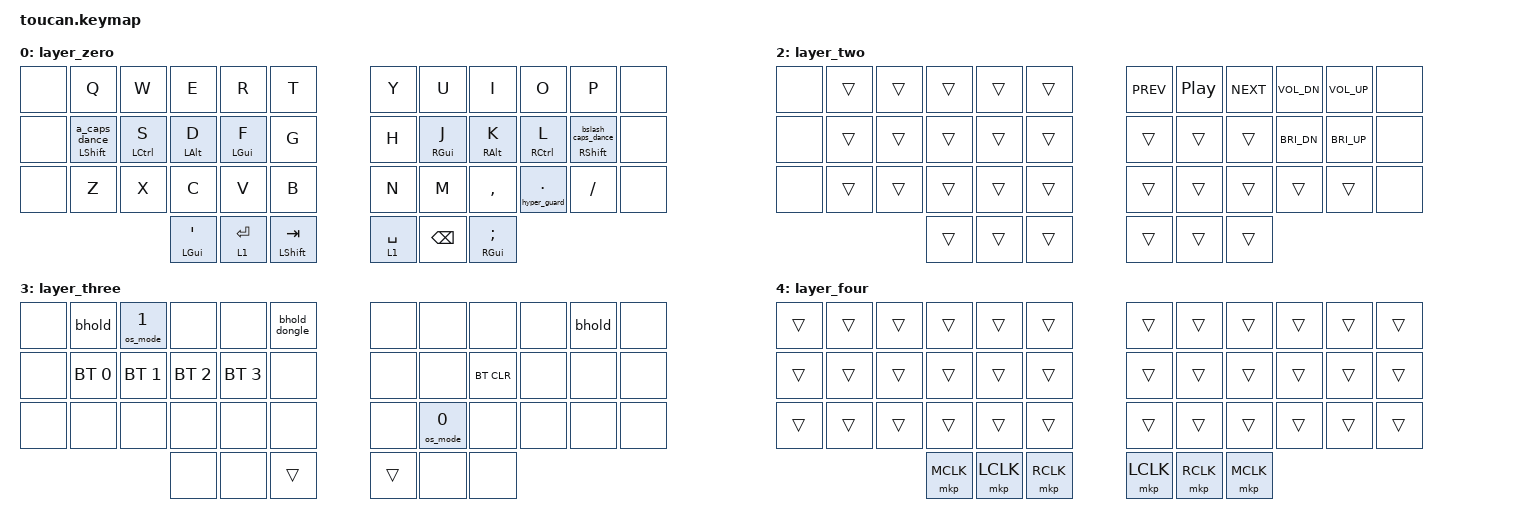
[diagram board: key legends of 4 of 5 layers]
#include <behaviors.dtsi>
#include <dt-bindings/zmk/keys.h>
#include <dt-bindings/zmk/bt.h>
#include <dt-bindings/zmk/outputs.h>
#include <dt-bindings/zmk/pointing.h>

// Home row mods macro
#define HRML(k1,k2,k3,k4) &hml LSHFT k1 &hml LCTRL k2  &hml LALT k3  &hml LGUI k4
#define HRMR(k1,k2,k3,k4) &hmr RGUI k1  &hmr RALT k2  &hmr RCTRL k3  &hmr RSHFT k4

// Key positions for positional hold-tap, kept for reference. Currently unused:
// the homerow mods below deliberately do NOT use cross-hand gating (see the
// note on `hml`). This is a ZMK Toucan2 (42 keys), so numbering below
// matches the shield's matrix transform -- see boards/shields/toucan/toucan.dtsi:
//   Row 0:  0   1  2  3  4  5  |  6  7  8  9 10  11
//   Row 1: 12  13 14 15 16 17  | 18 19 20 21 22  23
//   Row 2: 24  25 26 27 28 29  | 30 31 32 33 34  35
//   Thumbs:       36 37 38     | 39 40 41
// Positions 0, 11, 12, 23, 24, 35 are the outer pinky columns that exist on
// the Toucan's 42-key matrix but have no equivalent on the 36-key totemist
// this keymap was ported from -- they are bound to &none below.
#define KEYS_L 1 2 3 4 5 13 14 15 16 17 25 26 27 28 29    // left-hand inner keys
#define KEYS_R 6 7 8 9 10 18 19 20 21 22 30 31 32 33 34   // right-hand inner keys
#define THUMBS 36 37 38 39 40 41                          // thumb keys
#define UNUSED 0 11 12 23 24 35                           // extra pinky-column keys (no totemist equivalent)

// Layer names are for the USB dongle's OLED, so only the dongle build gets
// them (toucan_dongle.overlay defines TOUCAN_LAYER_NAMES). The left half's
// standalone gem screen keeps its stock `L#n` layer labels.
#ifdef TOUCAN_LAYER_NAMES
#define LAYER_NAME(label) display-name = label;
#else
#define LAYER_NAME(label)
#endif

#define L0 0
#define L1 1
#define L2 2
#define L3 3
#define L4 4

// Layer-tap, used by the left Enter/L1 and right Space/L1 thumbs.
//
// ZMK's stock `&lt` is `tap-preferred`, which only resolves a hold when the
// tapping term expires -- pressing and releasing another key while it is held
// does NOT trigger the hold. So a quick layer chord (hold the thumb, tap a
// key, release) completed inside 200ms emits SPACE plus that key instead of
// the layer keycode. `balanced` resolves the hold as soon as another key is
// pressed and released, which is exactly what a layer chord looks like.
&lt {
    flavor = "balanced";
    tapping-term-ms = <175>;
    quick-tap-ms = <125>;
};

/ {
    behaviors {
        // Thumb hold-tap: quote/Cmd on the left outer thumb and
        // semicolon/Cmd on the right outer thumb.
        //
        // Deliberately has NO `global-quick-tap` / `require-prior-idle-ms`.
        // Those make ZMK resolve the key to an *instant tap* whenever any other
        // key was pressed within the preceding window, no matter how long or
        // how hard the key is then held -- see is_quick_tap() in ZMK's
        // behavior_hold_tap.c. Since Shift is nearly always pressed immediately
        // after typing a letter, that reliably emitted TAB instead of SHIFT.
        //
        // Prior-idle gating is right for homerow mods (see hml/hmr below), but
        // wrong for thumbs, which are never pressed accidentally while typing.
        ht: hold_tap {
            label = "hold_tap";
            compatible = "zmk,behavior-hold-tap";
            #binding-cells = <2>;
            flavor = "balanced";
            tapping-term-ms = <175>;
            quick-tap-ms = <125>;
            bindings = <&kp>, <&kp>;
        };

        a_caps_dance: a_caps_dance {
            compatible = "zmk,behavior-tap-dance";
            #binding-cells = <0>;
            tapping-term-ms = <200>;
            bindings = <&kp A>, <&caps_word>;
        };

        bslash_caps_dance: bslash_caps_dance {
            compatible = "zmk,behavior-tap-dance";
            #binding-cells = <0>;
            tapping-term-ms = <200>;
            bindings = <&kp BSLH>, <&caps_word>;
        };

        a_shift: a_shift {
            compatible = "zmk,behavior-hold-tap";
            #binding-cells = <2>;
            flavor = "balanced";
            tapping-term-ms = <190>;
            quick-tap-ms = <120>;
            require-prior-idle-ms = <100>;
            bindings = <&kp>, <&a_caps_dance>;
        };

        bslash_shift: bslash_shift {
            compatible = "zmk,behavior-hold-tap";
            #binding-cells = <2>;
            flavor = "balanced";
            tapping-term-ms = <190>;
            quick-tap-ms = <120>;
            require-prior-idle-ms = <100>;
            bindings = <&kp>, <&bslash_caps_dance>;
        };

        // These symbol combos keep their output unchanged while Shift is held.
        lpar_fixed: lpar_fixed {
            compatible = "zmk,behavior-mod-morph";
            #binding-cells = <0>;
            bindings = <&kp LPAR>, <&kp LPAR>;
            mods = <(MOD_LSFT|MOD_RSFT)>;
        };
        rpar_fixed: rpar_fixed {
            compatible = "zmk,behavior-mod-morph";
            #binding-cells = <0>;
            bindings = <&kp RPAR>, <&kp RPAR>;
            mods = <(MOD_LSFT|MOD_RSFT)>;
        };
        lbkt_fixed: lbkt_fixed {
            compatible = "zmk,behavior-mod-morph";
            #binding-cells = <0>;
            bindings = <&kp LBKT>, <&kp LBKT>;
            mods = <(MOD_LSFT|MOD_RSFT)>;
        };
        rbkt_fixed: rbkt_fixed {
            compatible = "zmk,behavior-mod-morph";
            #binding-cells = <0>;
            bindings = <&kp RBKT>, <&kp RBKT>;
            mods = <(MOD_LSFT|MOD_RSFT)>;
        };
        lbrc_fixed: lbrc_fixed {
            compatible = "zmk,behavior-mod-morph";
            #binding-cells = <0>;
            bindings = <&kp LBRC>, <&kp LBRC>;
            mods = <(MOD_LSFT|MOD_RSFT)>;
        };
        rbrc_fixed: rbrc_fixed {
            compatible = "zmk,behavior-mod-morph";
            #binding-cells = <0>;
            bindings = <&kp RBRC>, <&kp RBRC>;
            mods = <(MOD_LSFT|MOD_RSFT)>;
        };
        minus_fixed: minus_fixed {
            compatible = "zmk,behavior-mod-morph";
            #binding-cells = <0>;
            bindings = <&kp MINUS>, <&kp MINUS>;
            mods = <(MOD_LSFT|MOD_RSFT)>;
        };
        equal_fixed: equal_fixed {
            compatible = "zmk,behavior-mod-morph";
            #binding-cells = <0>;
            bindings = <&kp EQUAL>, <&kp EQUAL>;
            mods = <(MOD_LSFT|MOD_RSFT)>;
        };
        under_fixed: under_fixed {
            compatible = "zmk,behavior-mod-morph";
            #binding-cells = <0>;
            bindings = <&kp UNDER>, <&kp UNDER>;
            mods = <(MOD_LSFT|MOD_RSFT)>;
        };
        plus_fixed: plus_fixed {
            compatible = "zmk,behavior-mod-morph";
            #binding-cells = <0>;
            bindings = <&kp PLUS>, <&kp PLUS>;
            mods = <(MOD_LSFT|MOD_RSFT)>;
        };

        // Homerow mods.
        //
        // NOTE: no `hold-trigger-key-positions` / `hold-trigger-on-release`.
        // Those implement urob's cross-hand ("timeless") positional hold-tap,
        // where a homerow mod can ONLY resolve as a hold if the next key is on
        // the opposite half. That gate is absolute -- there is no timeout
        // escape hatch -- so holding LGUI (F) and pressing C, both left hand,
        // can never become a hold and just emits "fc". That breaks the whole
        // left-hand shortcut cluster (CMD/CTRL + Q W A S Z X C V) and every
        // left-hand capital via LSHFT on A.
        //
        // With the positional gate removed, `require-prior-idle-ms` is the
        // main guard against false mods mid-word, and the tapping term becomes
        // the window in which a same-hand roll could still resolve as a hold
        // (balanced resolves on the other key's release). 190ms with a 100ms
        // prior-idle (was 220/150) biases toward HOLD, since missed holds
        // proved far more common than false ones.
        //
        // Trade-off: a fast same-hand roll that *starts* on the homerow after
        // >100ms idle ("as", "sad", "fad") can register a mod. If that becomes
        // the more annoying failure mode, re-add the two properties below
        // (KEYS_R THUMBS for hml, KEYS_L THUMBS for hmr) and use combos for
        // same-hand shortcuts, which is how urob handles it.
        hml: home_row_mod_left {
            label = "hrm_left";
            compatible = "zmk,behavior-hold-tap";
            #binding-cells = <2>;
            flavor = "balanced";
            tapping-term-ms = <190>;
            quick-tap-ms = <120>;
            require-prior-idle-ms = <100>;
            bindings = <&kp>, <&kp>;
        };

        hmd: home_row_mod_d {
            label = "hrm_d";
            compatible = "zmk,behavior-hold-tap";
            #binding-cells = <2>;
            flavor = "balanced";
            tapping-term-ms = <160>;
            quick-tap-ms = <120>;
            require-prior-idle-ms = <50>;
            bindings = <&kp>, <&kp>;
        };

        hmr: home_row_mod_right {
            label = "hrm_right";
            compatible = "zmk,behavior-hold-tap";
            #binding-cells = <2>;
            flavor = "balanced";
            tapping-term-ms = <190>;
            quick-tap-ms = <120>;
            require-prior-idle-ms = <100>;
            bindings = <&kp>, <&kp>;
        };

        // Software bootloader entry for the maintenance layer. This uses a
        // dedicated long-press behavior instead of `zmk,behavior-hold-tap`.
        // Both inner thumbs are hold-tap keys, and ZMK v0.3 rejects a second
        // hold-tap while either thumb remains held. Tap does nothing; a 2s+
        // hold invokes `&bootloader` with the original key's split source.
        //
        // This exists because ZMK behaviors with BEHAVIOR_LOCALITY_EVENT_SOURCE
        // (which &bootloader uses) execute on whichever half the triggering
        // key physically lives on, even though all keymap/behavior logic runs
        // on the central (left) half -- so position 10, physically on the
        // right board, reliably bootloaders the right half over BLE even
        // when its physical reset button doesn't.
        bhold: bootloader_hold {
            label = "bootloader_hold";
            compatible = "zmk,behavior-long-press";
            #binding-cells = <0>;
            duration-ms = <2000>;
            bindings = <&bootloader>;
        };

        // Same 2s hold, retargeted at the split central via `central`. In
        // dongle mode that is the keyless dongle, which otherwise has no way
        // into its UF2 bootloader short of opening its case to reach the reset
        // button. Standalone, the central is the left half, so this simply
        // duplicates the left pinky hold.
        bhold_dongle: bootloader_hold_dongle {
            compatible = "zmk,behavior-long-press";
            #binding-cells = <0>;
            duration-ms = <2000>;
            bindings = <&bootloader>;
            central;
        };
        // `&kp` that drops the key while Ctrl, Shift, Alt and GUI are all
        // held. Resting on the four left homerow mods resolves them all as
        // holds, and with `.` that is macOS's sysdiagnose chord, which kept
        // firing by accident. Any other modifier combination is unaffected.
        hyper_guard: hyper_guard {
            compatible = "zmk,behavior-hyper-guard";
            #binding-cells = <1>;
        };
    };

    combos {
        compatible = "zmk,combos";
        // Letter combos need both keys within 25ms (ZMK's default is 50ms), so
        // quick rolls while typing, like O then P, stay as plain letters.
        combo_esc_op {
            timeout-ms = <25>;
            key-positions = <9 10>;  // Combo o+p for ESCAPE
            bindings = <&kp ESC>;
        };
        combo_esc_qw {
            timeout-ms = <25>;
            key-positions = <1 2>;  // Combo q+w for ESCAPE
            bindings = <&kp ESC>;
        };
        // Symbol combos work on every layer and ignore held Shift.
        combo_left_paren {
            timeout-ms = <25>;
            key-positions = <27 28>;  // C+V
            bindings = <&lpar_fixed>;
        };
        combo_right_paren {
            timeout-ms = <25>;
            key-positions = <31 32>;  // M+COMMA
            bindings = <&rpar_fixed>;
        };
        combo_left_bracket {
            timeout-ms = <25>;
            key-positions = <15 16>;  // D+F
            bindings = <&lbkt_fixed>;
        };
        combo_right_bracket {
            timeout-ms = <25>;
            key-positions = <19 20>;  // J+K
            bindings = <&rbkt_fixed>;
        };
        combo_left_brace {
            timeout-ms = <25>;
            key-positions = <3 4>;  // E+R
            bindings = <&lbrc_fixed>;
        };
        combo_right_brace {
            timeout-ms = <25>;
            key-positions = <7 8>;  // U+I
            bindings = <&rbrc_fixed>;
        };
        combo_minus {
            timeout-ms = <25>;
            key-positions = <25 26>;  // Z+X
            bindings = <&minus_fixed>;
        };
        combo_equal {
            timeout-ms = <25>;
            key-positions = <33 34>;  // .+/
            bindings = <&equal_fixed>;
        };
        combo_underscore {
            timeout-ms = <25>;
            key-positions = <13 14>;  // A+S
            bindings = <&under_fixed>;
        };
        combo_plus {
            timeout-ms = <25>;
            key-positions = <21 22>;  // L+backslash
            bindings = <&plus_fixed>;
        };
        combo_maintenance_layer {
            timeout-ms = <100>;
            key-positions = <36 41>;  // Hold both far outer thumbs.
            bindings = <&mo L3>;
            layers = <L0 L1 L2>;
        };
    };


    keymap {
        compatible = "zmk,keymap";

        layer_zero {
            LAYER_NAME("ABC")
            bindings = <
        //     ╭───────────┬───────────┬───────────┬───────────┬───────────┬───────────╮   ╭───────────┬───────────┬───────────┬───────────┬───────────┬───────────╮
                &none       &kp Q       &kp W       &kp E       &kp R       &kp T           &kp Y       &kp U       &kp I       &kp O       &kp P       &none
        //     ├───────────├───────────├───────────├───────────├───────────├───────────┤   ├───────────├───────────├───────────├───────────├───────────├───────────┤
                &none       &a_shift LSHFT 0 &hml LCTRL S &hmd LALT D &hml LGUI F &kp G     &kp H       &hmr RGUI J &hmr RALT K &hmr RCTRL L &bslash_shift RSHFT 0 &none
        //     ├───────────├───────────├───────────├───────────├───────────├───────────┤   ├───────────├───────────├───────────├───────────├───────────├───────────┤
                &none       &kp Z       &kp X       &kp C       &kp V       &kp B           &kp N       &kp M       &kp COMMA   &hyper_guard DOT &kp FSLH    &none
        //     ╰───────────┴───────────┴───────────├───────────├───────────┼───────────┤   ├───────────├───────────┼───────────┴───────────┴───────────╯
                                                &ht LGUI SQT   &lt L1 RET &ht LSHFT TAB &lt L1 SPACE  &kp BSPC   &ht RGUI SEMI
        //                                         ╰───────────┴───────────┴───────────╯   ╰───────────┴───────────┴───────────╯
            >;
        };


        layer_one {
            LAYER_NAME("NUM")
            bindings = <
        //     ╭───────────┬───────────┬───────────┬───────────┬───────────┬───────────╮   ╭───────────┬───────────┬───────────┬───────────┬───────────┬───────────╮
                &none       &kp ESC     &kp N1      &kp N2      &kp N3      &trans          &trans      &trans      &kp UP      &kp MINUS   &kp EQUAL   &none
        //     ├───────────├───────────├───────────├───────────├───────────├───────────┤   ├───────────├───────────├───────────├───────────├───────────├───────────┤
                &none       HRML(GRAVE,     N4,         N5,         N6)     &trans          &trans      &kp LEFT    &kp DOWN    &kp RIGHT   &trans      &none
        //     ├───────────├───────────├───────────├───────────├───────────├───────────┤   ├───────────├───────────├───────────├───────────├───────────├───────────┤
                &none       &trans      &kp N7      &kp N8      &kp N9      &kp N0          &kp SEMI    &kp SQT     &kp LBKT    &kp RBKT    &trans      &none
        //     ╰───────────┴───────────┴───────────├───────────├───────────┼───────────┤   ├───────────├───────────┼───────────┴───────────┴───────────╯
                                                &ht LGUI GRAVE &trans     &trans          &trans      &trans      &trans
        //                                         ╰───────────┴───────────┴───────────╯   ╰───────────┴───────────┴───────────╯
            >;
        };



        layer_two {
            LAYER_NAME("MED")
            bindings = <
        //     ╭───────────┬───────────┬───────────┬───────────┬───────────┬───────────╮   ╭───────────┬───────────┬───────────┬───────────┬───────────┬───────────╮
                &none       &trans      &trans      &trans      &trans      &trans          &kp C_PREV  &kp C_PP    &kp C_NEXT  &kp C_VOL_DN   &kp C_VOL_UP   &none
        //     ├───────────├───────────├───────────├───────────├───────────├───────────┤   ├───────────├───────────├───────────├───────────├───────────├───────────┤
                &none       &trans      &trans      &trans      &trans      &trans          &trans      &trans      &trans      &kp C_BRI_DN   &kp C_BRI_UP   &none
        //     ├───────────├───────────├───────────├───────────├───────────├───────────┤   ├───────────├───────────├───────────├───────────├───────────├───────────┤
                &none       &trans      &trans      &trans      &trans      &trans          &trans      &trans      &trans      &trans      &trans      &none
        //     ╰───────────┴───────────┴───────────├───────────├───────────┼───────────┤   ├───────────├───────────┼───────────┴───────────┴───────────╯
                                                   &trans      &trans      &trans          &trans      &trans      &trans
        //                                         ╰───────────┴───────────┴───────────╯   ╰───────────┴───────────┴───────────╯
            >;
        };

        // Dedicated maintenance layer. Hold both far outer thumbs (positions
        // 36 and 41) to activate it. This leaves the center Shift + L1 thumb
        // chord completely untouched. Bluetooth controls retain their previous
        // physical positions where possible. The bootloader holds move to Q/P,
        // the real top pinky keys on the 36-key variant; hold the corresponding
        // side for two seconds to enter that half's UF2 bootloader.
        //
        // `M` selects macOS and `W` selects Windows for the active host.
        // Bluetooth clear moves from W to the now-free K key.
        // The choice is remembered per host (USB and each
        // BT profile) across reboots, so each machine only needs setting once.
        //
        // `T` is a third 2s bootloader hold, for the USB dongle in dongle mode
        // (the left half when standalone). It sits on the inner column, between
        // the two halves' pinky holds, like the dongle sits between the halves.
        layer_three {
            LAYER_NAME("SYS")
            bindings = <
                &none &bhold &os_mode 1 &none &none &bhold_dongle   &none &none &none &none &bhold &none
                &none &bt BT_SEL 0 &bt BT_SEL 1 &bt BT_SEL 2 &bt BT_SEL 3 &none   &none &none &bt BT_CLR &none &none &none
                &none &none &none &none &none &none   &none &os_mode 0 &none &none &none &none
                      &none &none &trans              &trans &none &none
            >;
        };

        // Mouse-click overlay layer. Auto-activated by `is_touching_processor`
        // (see toucan.dtsi) whenever a finger is touching the trackpad, so the
        // thumb cluster can left/middle/right-click without needing a
        // dedicated held key. Mirrors the stock Toucan2 keymap's mouse layer.
        layer_four {
            LAYER_NAME("PTR")
            bindings = <
                &trans &trans &trans &trans &trans &trans   &trans &trans &trans &trans &trans &trans
                &trans &trans &trans &trans &trans &trans   &trans &trans &trans &trans &trans &trans
                &trans &trans &trans &trans &trans &trans   &trans &trans &trans &trans &trans &trans
                       &mkp MCLK &mkp LCLK &mkp RCLK         &mkp LCLK &mkp RCLK &mkp MCLK
            >;
        };
    };
};
